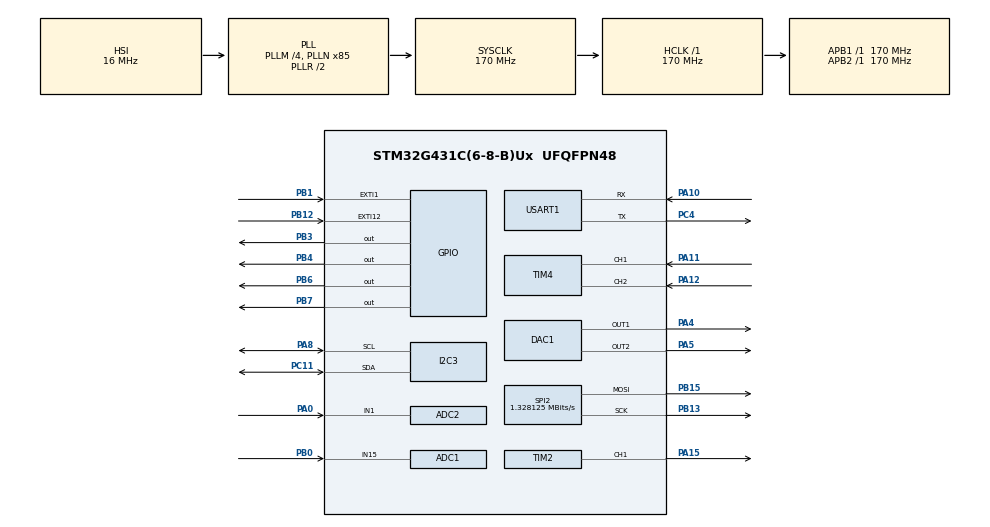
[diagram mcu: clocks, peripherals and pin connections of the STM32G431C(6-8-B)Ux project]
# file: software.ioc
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ADC1.Channel-5\#ChannelRegularConversion=ADC_CHANNEL_15
ADC1.DMAAccessModeView=ENABLE
ADC1.DMAContinuousRequests=ENABLE
ADC1.DataAlign=ADC_DATAALIGN_LEFT
ADC1.ExternalTrigConv=ADC_EXTERNALTRIG_T2_TRGO
ADC1.Mode=ADC_DUALMODE_REGSIMULT
ADC1.NbrOfConversionFlag=1
ADC1.Offset-5\#ChannelRegularConversion=2048
ADC1.OffsetNumber-5\#ChannelRegularConversion=ADC_OFFSET_1
ADC1.Rank-5\#ChannelRegularConversion=1
ADC1.SamplingTime-5\#ChannelRegularConversion=ADC_SAMPLETIME_2CYCLES_5
ADC1.master=1
ADC2.Channel-4\#ChannelRegularConversion=ADC_CHANNEL_1
ADC2.DMAAccessModeView=ENABLE
ADC2.DataAlign=ADC_DATAALIGN_LEFT
ADC2.Mode=ADC_DUALMODE_REGSIMULT
ADC2.NbrOfConversionFlag=1
ADC2.Offset-4\#ChannelRegularConversion=2048
ADC2.OffsetNumber-4\#ChannelRegularConversion=ADC_OFFSET_1
ADC2.Rank-4\#ChannelRegularConversion=1
ADC2.SamplingTime-4\#ChannelRegularConversion=ADC_SAMPLETIME_2CYCLES_5
CRC.InputDataInversionMode=CRC_INPUTDATA_INVERSION_NONE
DAC1.DAC_Channel-DAC_OUT2=DAC_CHANNEL_2
DAC1.DAC_DMADoubleDataMode-DAC_OUT1=DISABLE
DAC1.DAC_SignedFormat-DAC_OUT1=ENABLE
DAC1.DAC_Trigger_OUT1-DAC_OUT1=DAC_TRIGGER_T2_TRGO
Dma.ADC1.0.Direction=DMA_PERIPH_TO_MEMORY
Dma.ADC1.0.EventEnable=ENABLE
Dma.ADC1.0.Instance=DMA1_Channel1
Dma.ADC1.0.MemDataAlignment=DMA_MDATAALIGN_WORD
Dma.ADC1.0.MemInc=DMA_MINC_ENABLE
Dma.ADC1.0.Mode=DMA_CIRCULAR
Dma.ADC1.0.PeriphDataAlignment=DMA_PDATAALIGN_WORD
Dma.ADC1.0.PeriphInc=DMA_PINC_DISABLE
Dma.ADC1.0.Polarity=HAL_DMAMUX_REQ_GEN_RISING
Dma.ADC1.0.Priority=DMA_PRIORITY_LOW
Dma.ADC1.0.RequestNumber=1
Dma.ADC1.0.SignalID=NONE
Dma.ADC1.0.SyncEnable=DISABLE
Dma.ADC1.0.SyncPolarity=HAL_DMAMUX_SYNC_NO_EVENT
Dma.ADC1.0.SyncRequestNumber=1
Dma.ADC1.0.SyncSignalID=NONE
Dma.DAC1_CH1.1.Direction=DMA_MEMORY_TO_PERIPH
Dma.DAC1_CH1.1.EventEnable=DISABLE
Dma.DAC1_CH1.1.Instance=DMA1_Channel2
Dma.DAC1_CH1.1.MemDataAlignment=DMA_MDATAALIGN_HALFWORD
Dma.DAC1_CH1.1.MemInc=DMA_MINC_ENABLE
Dma.DAC1_CH1.1.Mode=DMA_CIRCULAR
Dma.DAC1_CH1.1.PeriphDataAlignment=DMA_PDATAALIGN_WORD
Dma.DAC1_CH1.1.PeriphInc=DMA_PINC_DISABLE
Dma.DAC1_CH1.1.Polarity=HAL_DMAMUX_REQ_GEN_RISING
Dma.DAC1_CH1.1.Priority=DMA_PRIORITY_LOW
Dma.DAC1_CH1.1.RequestNumber=1
Dma.DAC1_CH1.1.SignalID=NONE
Dma.DAC1_CH1.1.SyncEnable=DISABLE
Dma.DAC1_CH1.1.SyncPolarity=HAL_DMAMUX_SYNC_NO_EVENT
Dma.DAC1_CH1.1.SyncRequestNumber=1
Dma.DAC1_CH1.1.SyncSignalID=NONE
Dma.Request0=ADC1
Dma.Request1=DAC1_CH1
I2C3.Timing=0x40B285C2
Mcu.Family=STM32G4
Mcu.Name=STM32G431C(6-8-B)Ux
Mcu.Package=UFQFPN48
NVIC.DMA1_Channel1_IRQn=true\:0\:0\:true\:true\:true\:1\:false\:true\:true
NVIC.DMA1_Channel2_IRQn=true\:0\:0\:true\:true\:true\:2\:false\:true\:true
NVIC.DMAMUX_OVR_IRQn=true\:0\:0\:false\:false\:true\:false\:true\:true
NVIC.EXTI15_10_IRQn=true\:0\:0\:false\:false\:true\:true\:true\:true
NVIC.EXTI1_IRQn=true\:0\:0\:false\:false\:true\:true\:true\:true
NVIC.PriorityGroup=NVIC_PRIORITYGROUP_4
NVIC.TIM4_IRQn=true\:0\:0\:false\:false\:true\:true\:true\:true
NVIC.TIM6_DAC_IRQn=true\:0\:0\:false\:false\:true\:true\:true\:true
PA0.Mode=IN1-Single-Ended
PA0.Signal=ADC2_IN1
PA10.Mode=Asynchronous
PA10.Signal=USART1_RX
PA11.GPIO_ModeDefaultPP=GPIO_MODE_AF_PP
PA11.GPIO_PuPd=GPIO_PULLUP
PA11.GPIO_Speed=GPIO_SPEED_FREQ_LOW
PA11.Signal=S_TIM4_CH1
PA12.GPIO_ModeDefaultPP=GPIO_MODE_AF_PP
PA12.GPIO_PuPd=GPIO_PULLUP
PA12.GPIO_Speed=GPIO_SPEED_FREQ_LOW
PA12.Signal=S_TIM4_CH2
PA15.Signal=S_TIM2_CH1
PA4.Signal=COMP_DAC11_group
PA5.Signal=COMP_DAC12_group
PA8.GPIO_Pu=GPIO_PULLUP
PA8.GPIO_Speed=GPIO_SPEED_FREQ_HIGH
PA8.Mode=I2C
PA8.Signal=I2C3_SCL
PB0.Mode=IN15-Single-Ended
PB0.Signal=ADC1_IN15
PB1.Signal=GPXTI1
PB12.GPIO_ModeDefaultEXTI=GPIO_MODE_IT_FALLING
PB12.GPIO_PuPd=GPIO_PULLUP
PB12.Signal=GPXTI12
PB13.Mode=TX_Only_Simplex_Unidirect_Master
PB13.Signal=SPI2_SCK
PB15.Mode=TX_Only_Simplex_Unidirect_Master
PB15.Signal=SPI2_MOSI
PB3.Signal=GPIO_Output
PB4.Signal=GPIO_Output
PB6.Signal=GPIO_Output
PB7.Signal=GPIO_Output
PC11.GPIO_Pu=GPIO_PULLUP
PC11.GPIO_Speed=GPIO_SPEED_FREQ_HIGH
PC11.Mode=I2C
PC11.Signal=I2C3_SDA
PC14-OSC32_IN.Mode=LSE-External-Oscillator
PC14-OSC32_IN.Signal=RCC_OSC32_IN
PC15-OSC32_OUT.Mode=LSE-External-Oscillator
PC15-OSC32_OUT.Signal=RCC_OSC32_OUT
PC4.Mode=Asynchronous
PC4.Signal=USART1_TX
PF0-OSC_IN.Mode=HSE-External-Oscillator
PF0-OSC_IN.Signal=RCC_OSC_IN
PF1-OSC_OUT.Mode=HSE-External-Oscillator
PF1-OSC_OUT.Signal=RCC_OSC_OUT
ProjectManager.HeapSize=0x200
ProjectManager.StackSize=0x400
ProjectManager.TargetToolchain=Makefile
RCC.ADC12Freq_Value=170000000
RCC.AHBFreq_Value=170000000
RCC.APB1Freq_Value=170000000
RCC.APB1TimFreq_Value=170000000
RCC.APB2Freq_Value=170000000
RCC.APB2TimFreq_Value=170000000
RCC.CortexFreq_Value=170000000
RCC.EXTERNAL_CLOCK_VALUE=12288000
RCC.HCLKFreq_Value=170000000
RCC.HSE_VALUE=8000000
RCC.HSI48_VALUE=48000000
RCC.HSI_VALUE=16000000
RCC.PLLM=RCC_PLLM_DIV4
RCC.PLLN=85
RCC.SYSCLKFreq_VALUE=170000000
RCC.SYSCLKSource=RCC_SYSCLKSOURCE_PLLCLK
RCC.USBFreq_Value=170000000
RCC.VCOOutputFreq_Value=340000000
SH.COMP_DAC11_group.0=DAC1_OUT1,DAC_OUT1
SH.COMP_DAC12_group.0=DAC1_OUT2,DAC_OUT2
SH.S_TIM2_CH1.0=TIM2_CH1,PWM Generation1 CH1
SH.S_TIM4_CH1.0=TIM4_CH1,Encoder_Interface
SH.S_TIM4_CH2.0=TIM4_CH2,Encoder_Interface
SPI2.BaudRatePrescaler=SPI_BAUDRATEPRESCALER_128
SPI2.CLKPolarity=SPI_POLARITY_HIGH
SPI2.CalculateBaudRate=1.328125 MBits/s
SPI2.DataSize=SPI_DATASIZE_8BIT
SPI2.Direction=SPI_DIRECTION_2LINES
SPI2.FirstBit=SPI_FIRSTBIT_MSB
SPI2.Mode=SPI_MODE_MASTER
SPI2.NSSPMode=SPI_NSS_PULSE_DISABLE
SPI2.VirtualType=VM_MASTER
TIM2.Channel-PWM\ Generation1\ CH1=TIM_CHANNEL_1
TIM2.OCFastMode_PWM-PWM\ Generation1\ CH1=TIM_OCFAST_ENABLE
TIM2.PeriodNoDither=1600
TIM2.TIM_MasterOutputTrigger=TIM_TRGO_UPDATE
TIM2.TIM_MasterSlaveMode=TIM_MASTERSLAVEMODE_DISABLE
TIM4.EncoderMode=TIM_ENCODERMODE_TI12
USART1.VirtualMode-Asynchronous=VM_ASYNC
VP_CORDIC_VS_CORDIC.Mode=CORDIC_Activate
VP_CRC_VS_CRC.Mode=CRC_Activate
VP_SYS_VS_DBSignals.Mode=DisableDeadBatterySignals
board=custom

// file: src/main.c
/* USER CODE BEGIN Header */
/**
 ******************************************************************************
 * @file					 : main.c
 * @brief					: Main program body
 ******************************************************************************
 * @attention
 *
 * Copyright (c) 2025 STMicroelectronics.
 * All rights reserved.
 *
 * This software is licensed under undeclaredterms that can be found in the
 *LICENSE file in the root directory of this software component. If no LICENSE
 *file comes with this software, it is provided AS-IS.
 *
 ******************************************************************************
 */
/* USER CODE END Header */
#include "main.h"

/* USER CODE BEGIN Includes */

#include <arm_const_structs.h>
#include <math.h>
#include <stdio.h>
#include <stdlib.h>
#include <stm32g4xx_ll_cordic.h>

#include "arm_math.h"

/* USER CODE END Includes */

ADC_HandleTypeDef hadc1;
ADC_HandleTypeDef hadc2;
DMA_HandleTypeDef hdma_adc1;

CORDIC_HandleTypeDef hcordic;

CRC_HandleTypeDef hcrc;

DAC_HandleTypeDef hdac1;
DMA_HandleTypeDef hdma_dac1_ch1;

I2C_HandleTypeDef hi2c3;

SPI_HandleTypeDef hspi2;

TIM_HandleTypeDef htim2;
TIM_HandleTypeDef htim4;

UART_HandleTypeDef huart1;

void SystemClock_Config(void);
static void MX_GPIO_Init(void);
static void MX_DMA_Init(void);
static void MX_DAC1_Init(void);
static void MX_I2C3_Init(void);
static void MX_USART1_UART_Init(void);
static void MX_TIM2_Init(void);
static void MX_TIM4_Init(void);
static void MX_CORDIC_Init(void);
static void MX_SPI2_Init(void);
static void MX_ADC1_Init(void);
static void MX_ADC2_Init(void);
static void MX_CRC_Init(void);
static void MX_NVIC_Init(void);

int main(void) {

  /* MCU
   * Configuration--------------------------------------------------------*/

  /* Reset of all peripherals, Initializes the Flash interface and the
   * Systick.
   */
  HAL_Init();

  /* Configure the system clock */
  SystemClock_Config();

  /* Initialize all configured peripherals */
  MX_GPIO_Init();
  MX_DMA_Init();
  MX_DAC1_Init();
  MX_I2C3_Init();
  MX_USART1_UART_Init();
  MX_TIM2_Init();
  MX_TIM4_Init();
  MX_CORDIC_Init();
  MX_SPI2_Init();
  MX_ADC1_Init();
  MX_ADC2_Init();
  MX_CRC_Init();

  /* Initialize interrupts */
  MX_NVIC_Init();
  /* USER CODE BEGIN 2 */

  // Exemple d'utilisation de CMSIS-DSP
  float32_t input_array[5] = {1.0f, 2.0f, 3.0f, 4.0f, 5.0f};
  float32_t mean_value;

  // Calcul de la moyenne avec CMSIS-DSP
  arm_mean_f32(input_array, 5, &mean_value);

  // La valeur moyenne est maintenant dans mean_value (devrait être 3.0)

  /* USER CODE END 2 */

  /* Infinite loop */
  while (1) {

  }
}

void SystemClock_Config(void) {
  RCC_OscInitTypeDef RCC_OscInitStruct = {0};
  RCC_ClkInitTypeDef RCC_ClkInitStruct = {0};

  /** Configure the main internal regulator output voltage
   */
  HAL_PWREx_ControlVoltageScaling(PWR_REGULATOR_VOLTAGE_SCALE1_BOOST);

  /** Initializes the RCC Oscillators according to the specified parameters
   * in the RCC_OscInitTypeDef structure.
   */
  RCC_OscInitStruct.OscillatorType = RCC_OSCILLATORTYPE_HSI;
  RCC_OscInitStruct.HSIState = RCC_HSI_ON;
  RCC_OscInitStruct.HSICalibrationValue = RCC_HSICALIBRATION_DEFAULT;
  RCC_OscInitStruct.PLL.PLLState = RCC_PLL_ON;
  RCC_OscInitStruct.PLL.PLLSource = RCC_PLLSOURCE_HSI;
  RCC_OscInitStruct.PLL.PLLM = RCC_PLLM_DIV4;
  RCC_OscInitStruct.PLL.PLLN = 85;
  RCC_OscInitStruct.PLL.PLLP = RCC_PLLP_DIV2;
  RCC_OscInitStruct.PLL.PLLQ = RCC_PLLQ_DIV2;
  RCC_OscInitStruct.PLL.PLLR = RCC_PLLR_DIV2;
  if (HAL_RCC_OscConfig(&RCC_OscInitStruct) != HAL_OK) {
    Error_Handler();
  }

  /** Initializes the CPU, AHB and APB buses clocks
   */
  RCC_ClkInitStruct.ClockType = RCC_CLOCKTYPE_HCLK | RCC_CLOCKTYPE_SYSCLK |
                                RCC_CLOCKTYPE_PCLK1 | RCC_CLOCKTYPE_PCLK2;
  RCC_ClkInitStruct.SYSCLKSource = RCC_SYSCLKSOURCE_PLLCLK;
  RCC_ClkInitStruct.AHBCLKDivider = RCC_SYSCLK_DIV1;
  RCC_ClkInitStruct.APB1CLKDivider = RCC_HCLK_DIV1;
  RCC_ClkInitStruct.APB2CLKDivider = RCC_HCLK_DIV1;

  if (HAL_RCC_ClockConfig(&RCC_ClkInitStruct, FLASH_LATENCY_4) != HAL_OK) {
    Error_Handler();
  }
}

/**
 * @brief NVIC Configuration.
 * @retval None
 */
static void MX_NVIC_Init(void) {
  /* DMA1_Channel1_IRQn interrupt configuration */
  HAL_NVIC_SetPriority(DMA1_Channel1_IRQn, 0, 0);
  HAL_NVIC_EnableIRQ(DMA1_Channel1_IRQn);
  /* DMA1_Channel2_IRQn interrupt configuration */
  HAL_NVIC_SetPriority(DMA1_Channel2_IRQn, 0, 0);
  HAL_NVIC_EnableIRQ(DMA1_Channel2_IRQn);
}

static void MX_ADC1_Init(void) {

  ADC_MultiModeTypeDef multimode = {0};
  ADC_ChannelConfTypeDef sConfig = {0};

  /** Common config
   */
  hadc1.Instance = ADC1;
  hadc1.Init.ClockPrescaler = ADC_CLOCK_SYNC_PCLK_DIV4;
  hadc1.Init.Resolution = ADC_RESOLUTION_12B;
  hadc1.Init.DataAlign = ADC_DATAALIGN_LEFT;
  hadc1.Init.GainCompensation = 0;
  hadc1.Init.ScanConvMode = ADC_SCAN_DISABLE;
  hadc1.Init.EOCSelection = ADC_EOC_SINGLE_CONV;
  hadc1.Init.LowPowerAutoWait = DISABLE;
  hadc1.Init.ContinuousConvMode = DISABLE;
  hadc1.Init.NbrOfConversion = 1;
  hadc1.Init.DiscontinuousConvMode = DISABLE;
  hadc1.Init.ExternalTrigConv = ADC_EXTERNALTRIG_T2_TRGO;
  hadc1.Init.ExternalTrigConvEdge = ADC_EXTERNALTRIGCONVEDGE_RISING;
  hadc1.Init.DMAContinuousRequests = ENABLE;
  hadc1.Init.Overrun = ADC_OVR_DATA_PRESERVED;
  hadc1.Init.OversamplingMode = DISABLE;
  if (HAL_ADC_Init(&hadc1) != HAL_OK) {
    Error_Handler();
  }

  /** Configure the ADC multi-mode
   */
  multimode.Mode = ADC_DUALMODE_REGSIMULT;
  multimode.DMAAccessMode = ADC_DMAACCESSMODE_12_10_BITS;
  multimode.TwoSamplingDelay = ADC_TWOSAMPLINGDELAY_1CYCLE;
  if (HAL_ADCEx_MultiModeConfigChannel(&hadc1, &multimode) != HAL_OK) {
    Error_Handler();
  }

  /** Configure Regular Channel
   */
  sConfig.Channel = ADC_CHANNEL_15;
  sConfig.Rank = ADC_REGULAR_RANK_1;
  sConfig.SamplingTime = ADC_SAMPLETIME_2CYCLES_5;
  sConfig.SingleDiff = ADC_SINGLE_ENDED;
  sConfig.OffsetNumber = ADC_OFFSET_1;
  sConfig.Offset = 2048;
  sConfig.OffsetSign = ADC_OFFSET_SIGN_NEGATIVE;
  sConfig.OffsetSaturation = DISABLE;
  if (HAL_ADC_ConfigChannel(&hadc1, &sConfig) != HAL_OK) {
    Error_Handler();
  }
}

static void MX_ADC2_Init(void) {

  ADC_ChannelConfTypeDef sConfig = {0};

  /** Common config
   */
  hadc2.Instance = ADC2;
  hadc2.Init.ClockPrescaler = ADC_CLOCK_SYNC_PCLK_DIV4;
  hadc2.Init.Resolution = ADC_RESOLUTION_12B;
  hadc2.Init.DataAlign = ADC_DATAALIGN_LEFT;
  hadc2.Init.GainCompensation = 0;
  hadc2.Init.ScanConvMode = ADC_SCAN_DISABLE;
  hadc2.Init.EOCSelection = ADC_EOC_SINGLE_CONV;
  hadc2.Init.LowPowerAutoWait = DISABLE;
  hadc2.Init.ContinuousConvMode = DISABLE;
  hadc2.Init.NbrOfConversion = 1;
  hadc2.Init.DiscontinuousConvMode = DISABLE;
  hadc2.Init.DMAContinuousRequests = DISABLE;
  hadc2.Init.Overrun = ADC_OVR_DATA_PRESERVED;
  hadc2.Init.OversamplingMode = DISABLE;
  if (HAL_ADC_Init(&hadc2) != HAL_OK) {
    Error_Handler();
  }

  /** Configure Regular Channel
   */
  sConfig.Channel = ADC_CHANNEL_1;
  sConfig.Rank = ADC_REGULAR_RANK_1;
  sConfig.SamplingTime = ADC_SAMPLETIME_2CYCLES_5;
  sConfig.SingleDiff = ADC_SINGLE_ENDED;
  sConfig.OffsetNumber = ADC_OFFSET_1;
  sConfig.Offset = 2048;
  sConfig.OffsetSign = ADC_OFFSET_SIGN_NEGATIVE;
  sConfig.OffsetSaturation = DISABLE;
  if (HAL_ADC_ConfigChannel(&hadc2, &sConfig) != HAL_OK) {
    Error_Handler();
  }
}

static void MX_CORDIC_Init(void) {

  hcordic.Instance = CORDIC;
  if (HAL_CORDIC_Init(&hcordic) != HAL_OK) {
    Error_Handler();
  }
}

static void MX_CRC_Init(void) {

  hcrc.Instance = CRC;
  hcrc.Init.DefaultPolynomialUse = DEFAULT_POLYNOMIAL_ENABLE;
  hcrc.Init.DefaultInitValueUse = DEFAULT_INIT_VALUE_ENABLE;
  hcrc.Init.InputDataInversionMode = CRC_INPUTDATA_INVERSION_NONE;
  hcrc.Init.OutputDataInversionMode = CRC_OUTPUTDATA_INVERSION_DISABLE;
  hcrc.InputDataFormat = CRC_INPUTDATA_FORMAT_BYTES;
  if (HAL_CRC_Init(&hcrc) != HAL_OK) {
    Error_Handler();
  }
}

static void MX_DAC1_Init(void) {

  DAC_ChannelConfTypeDef sConfig = {0};

  /** DAC Initialization
   */
  hdac1.Instance = DAC1;
  if (HAL_DAC_Init(&hdac1) != HAL_OK) {
    Error_Handler();
  }

  /** DAC channel OUT1 config
   */
  sConfig.DAC_HighFrequency = DAC_HIGH_FREQUENCY_INTERFACE_MODE_AUTOMATIC;
  sConfig.DAC_DMADoubleDataMode = DISABLE;
  sConfig.DAC_SignedFormat = ENABLE;
  sConfig.DAC_SampleAndHold = DAC_SAMPLEANDHOLD_DISABLE;
  sConfig.DAC_Trigger = DAC_TRIGGER_T2_TRGO;
  sConfig.DAC_Trigger2 = DAC_TRIGGER_NONE;
  sConfig.DAC_OutputBuffer = DAC_OUTPUTBUFFER_ENABLE;
  sConfig.DAC_ConnectOnChipPeripheral = DAC_CHIPCONNECT_EXTERNAL;
  sConfig.DAC_UserTrimming = DAC_TRIMMING_FACTORY;
  if (HAL_DAC_ConfigChannel(&hdac1, &sConfig, DAC_CHANNEL_1) != HAL_OK) {
    Error_Handler();
  }

  /** DAC channel OUT2 config
   */
  sConfig.DAC_SignedFormat = DISABLE;
  sConfig.DAC_Trigger = DAC_TRIGGER_NONE;
  if (HAL_DAC_ConfigChannel(&hdac1, &sConfig, DAC_CHANNEL_2) != HAL_OK) {
    Error_Handler();
  }
}

static void MX_I2C3_Init(void) {

  hi2c3.Instance = I2C3;
  hi2c3.Init.Timing = 0x40B285C2;
  hi2c3.Init.OwnAddress1 = 0;
  hi2c3.Init.AddressingMode = I2C_ADDRESSINGMODE_7BIT;
  hi2c3.Init.DualAddressMode = I2C_DUALADDRESS_DISABLE;
  hi2c3.Init.OwnAddress2 = 0;
  hi2c3.Init.OwnAddress2Masks = I2C_OA2_NOMASK;
  hi2c3.Init.GeneralCallMode = I2C_GENERALCALL_DISABLE;
  hi2c3.Init.NoStretchMode = I2C_NOSTRETCH_DISABLE;
  if (HAL_I2C_Init(&hi2c3) != HAL_OK) {
    Error_Handler();
  }

  /** Configure Analogue filter
   */
  if (HAL_I2CEx_ConfigAnalogFilter(&hi2c3, I2C_ANALOGFILTER_ENABLE) != HAL_OK) {
    Error_Handler();
  }

  /** Configure Digital filter
   */
  if (HAL_I2CEx_ConfigDigitalFilter(&hi2c3, 0) != HAL_OK) {
    Error_Handler();
  }
}

static void MX_SPI2_Init(void) {

  /* SPI2 parameter configuration*/
  hspi2.Instance = SPI2;
  hspi2.Init.Mode = SPI_MODE_MASTER;
  hspi2.Init.Direction = SPI_DIRECTION_2LINES;
  hspi2.Init.DataSize = SPI_DATASIZE_8BIT;
  hspi2.Init.CLKPolarity = SPI_POLARITY_HIGH;
  hspi2.Init.CLKPhase = SPI_PHASE_1EDGE;
  hspi2.Init.NSS = SPI_NSS_SOFT;
  hspi2.Init.BaudRatePrescaler = SPI_BAUDRATEPRESCALER_128;
  hspi2.Init.FirstBit = SPI_FIRSTBIT_MSB;
  hspi2.Init.TIMode = SPI_TIMODE_DISABLE;
  hspi2.Init.CRCCalculation = SPI_CRCCALCULATION_DISABLE;
  hspi2.Init.CRCPolynomial = 7;
  hspi2.Init.CRCLength = SPI_CRC_LENGTH_DATASIZE;
  hspi2.Init.NSSPMode = SPI_NSS_PULSE_DISABLE;
  if (HAL_SPI_Init(&hspi2) != HAL_OK) {
    Error_Handler();
  }
}

static void MX_TIM2_Init(void) {

  TIM_MasterConfigTypeDef sMasterConfig = {0};
  TIM_OC_InitTypeDef sConfigOC = {0};

  htim2.Instance = TIM2;
  htim2.Init.Prescaler = 0;
  htim2.Init.CounterMode = TIM_COUNTERMODE_UP;
  htim2.Init.Period = 1600;
  htim2.Init.ClockDivision = TIM_CLOCKDIVISION_DIV1;
  htim2.Init.AutoReloadPreload = TIM_AUTORELOAD_PRELOAD_DISABLE;
  if (HAL_TIM_PWM_Init(&htim2) != HAL_OK) {
    Error_Handler();
  }
  sMasterConfig.MasterOutputTrigger = TIM_TRGO_UPDATE;
  sMasterConfig.MasterSlaveMode = TIM_MASTERSLAVEMODE_DISABLE;
  if (HAL_TIMEx_MasterConfigSynchronization(&htim2, &sMasterConfig) != HAL_OK) {
    Error_Handler();
  }
  sConfigOC.OCMode = TIM_OCMODE_PWM1;
  sConfigOC.Pulse = 0;
  sConfigOC.OCPolarity = TIM_OCPOLARITY_HIGH;
  sConfigOC.OCFastMode = TIM_OCFAST_ENABLE;
  if (HAL_TIM_PWM_ConfigChannel(&htim2, &sConfigOC, TIM_CHANNEL_1) != HAL_OK) {
    Error_Handler();
  }
  HAL_TIM_MspPostInit(&htim2);
}

static void MX_TIM4_Init(void) {

  TIM_Encoder_InitTypeDef sConfig = {0};
  TIM_MasterConfigTypeDef sMasterConfig = {0};

  htim4.Instance = TIM4;
  htim4.Init.Prescaler = 0;
  htim4.Init.CounterMode = TIM_COUNTERMODE_UP;
  htim4.Init.Period = 65535;
  htim4.Init.ClockDivision = TIM_CLOCKDIVISION_DIV1;
  htim4.Init.AutoReloadPreload = TIM_AUTORELOAD_PRELOAD_DISABLE;
  sConfig.EncoderMode = TIM_ENCODERMODE_TI12;
  sConfig.IC1Polarity = TIM_ICPOLARITY_RISING;
  sConfig.IC1Selection = TIM_ICSELECTION_DIRECTTI;
  sConfig.IC1Prescaler = TIM_ICPSC_DIV1;
  sConfig.IC1Filter = 0;
  sConfig.IC2Polarity = TIM_ICPOLARITY_RISING;
  sConfig.IC2Selection = TIM_ICSELECTION_DIRECTTI;
  sConfig.IC2Prescaler = TIM_ICPSC_DIV1;
  sConfig.IC2Filter = 0;
  if (HAL_TIM_Encoder_Init(&htim4, &sConfig) != HAL_OK) {
    Error_Handler();
  }
  sMasterConfig.MasterOutputTrigger = TIM_TRGO_RESET;
  sMasterConfig.MasterSlaveMode = TIM_MASTERSLAVEMODE_DISABLE;
  if (HAL_TIMEx_MasterConfigSynchronization(&htim4, &sMasterConfig) != HAL_OK) {
    Error_Handler();
  }
}

static void MX_USART1_UART_Init(void) {

  huart1.Instance = USART1;
  huart1.Init.BaudRate = 115200;
  huart1.Init.WordLength = UART_WORDLENGTH_8B;
  huart1.Init.StopBits = UART_STOPBITS_1;
  huart1.Init.Parity = UART_PARITY_NONE;
  huart1.Init.Mode = UART_MODE_TX_RX;
  huart1.Init.HwFlowCtl = UART_HWCONTROL_NONE;
  huart1.Init.OverSampling = UART_OVERSAMPLING_16;
  huart1.Init.OneBitSampling = UART_ONE_BIT_SAMPLE_DISABLE;
  huart1.Init.ClockPrescaler = UART_PRESCALER_DIV1;
  huart1.AdvancedInit.AdvFeatureInit = UART_ADVFEATURE_NO_INIT;
  if (HAL_UART_Init(&huart1) != HAL_OK) {
    Error_Handler();
  }
  if (HAL_UARTEx_SetTxFifoThreshold(&huart1, UART_TXFIFO_THRESHOLD_1_8) !=
      HAL_OK) {
    Error_Handler();
  }
  if (HAL_UARTEx_SetRxFifoThreshold(&huart1, UART_RXFIFO_THRESHOLD_1_8) !=
      HAL_OK) {
    Error_Handler();
  }
  if (HAL_UARTEx_DisableFifoMode(&huart1) != HAL_OK) {
    Error_Handler();
  }
}

static void MX_DMA_Init(void) {
  /* DMA controller clock enable */
  __HAL_RCC_DMAMUX1_CLK_ENABLE();
  __HAL_RCC_DMA1_CLK_ENABLE();

  /* DMA interrupt init */
  /* DMAMUX_OVR_IRQn interrupt configuration */
  HAL_NVIC_SetPriority(DMAMUX_OVR_IRQn, 0, 0);
  HAL_NVIC_EnableIRQ(DMAMUX_OVR_IRQn);
}

static void MX_GPIO_Init(void) {
  GPIO_InitTypeDef GPIO_InitStruct = {0};

  /* GPIO Ports Clock Enable */
  __HAL_RCC_GPIOC_CLK_ENABLE();
  __HAL_RCC_GPIOF_CLK_ENABLE();
  __HAL_RCC_GPIOA_CLK_ENABLE();
  __HAL_RCC_GPIOB_CLK_ENABLE();

  /*Configure GPIO pin Output Level */
  HAL_GPIO_WritePin(GPIOB, GPIO_PIN_3 | GPIO_PIN_4 | GPIO_PIN_6 | GPIO_PIN_7,
                    GPIO_PIN_RESET);

  /*Configure GPIO pin : PB1 */
  GPIO_InitStruct.Pin = GPIO_PIN_1;
  GPIO_InitStruct.Mode = GPIO_MODE_IT_RISING;
  GPIO_InitStruct.Pull = GPIO_NOPULL;
  HAL_GPIO_Init(GPIOB, &GPIO_InitStruct);

  /*Configure GPIO pin : PB12 */
  GPIO_InitStruct.Pin = GPIO_PIN_12;
  GPIO_InitStruct.Mode = GPIO_MODE_IT_FALLING;
  GPIO_InitStruct.Pull = GPIO_PULLUP;
  HAL_GPIO_Init(GPIOB, &GPIO_InitStruct);

  /*Configure GPIO pins : PB3 PB4 PB6 PB7 */
  GPIO_InitStruct.Pin = GPIO_PIN_3 | GPIO_PIN_4 | GPIO_PIN_6 | GPIO_PIN_7;
  GPIO_InitStruct.Mode = GPIO_MODE_OUTPUT_PP;
  GPIO_InitStruct.Pull = GPIO_NOPULL;
  GPIO_InitStruct.Speed = GPIO_SPEED_FREQ_LOW;
  HAL_GPIO_Init(GPIOB, &GPIO_InitStruct);

  /* EXTI interrupt init*/
  HAL_NVIC_SetPriority(EXTI1_IRQn, 0, 0);
  HAL_NVIC_EnableIRQ(EXTI1_IRQn);

  HAL_NVIC_SetPriority(EXTI15_10_IRQn, 0, 0);
  HAL_NVIC_EnableIRQ(EXTI15_10_IRQn);

}

void Error_Handler(void) {
  /* USER CODE BEGIN Error_Handler_Debug */
  /* User can add his own implementation to report the HAL error return state
   */
  __disable_irq();
  while (1) {
  }
  /* USER CODE END Error_Handler_Debug */
}
#ifdef USE_FULL_ASSERT
/**
 * @brief  Reports the name of the source file and the source line number
 *         where the assert_param error has occurred.
 * @param  file: pointer to the source file name
 * @param  line: assert_param error line source number
 * @retval None
 */
void assert_failed(uint8_t* file, uint32_t line) {
  /* USER CODE BEGIN 6 */
  /* User can add his own implementation to report the file name and line
           number, ex: printf("Wrong parameters value: file %s on line
     %d\r\n", file, line) */
  /* USER CODE END 6 */
}
#endif /* USE_FULL_ASSERT */
